VERSION ""

NS_ :

BS_:

BU_: VCAN2_00 VCAN2_0B

BO_ 2565866755 ETC2: 8 Vector__XXX
 SG_ TransCurrentGear : 24|8@1+ (1,-125) [-125|125] "" Vector__XXX

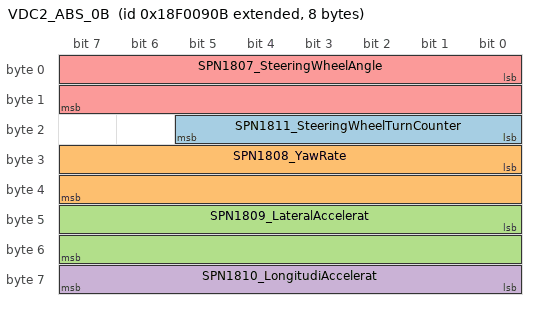
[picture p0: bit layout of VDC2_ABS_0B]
BO_ 2565867787 VDC2_ABS_0B: 8 VCAN2_0B
 SG_ SPN1811_SteeringWheelTurnCounter : 16|6@1+ (1,-32) [-32|31] "turns" Vector__XXX
 SG_ SPN1808_YawRate : 24|16@1+ (0.0069907,-224.599459) [-224.599459|233.5360655] "deg/s" Vector__XXX
 SG_ SPN1809_LateralAccelerat : 40|16@1+ (0.00048828125,-15.687) [-15.687|16.31251171875] "m/s^2" Vector__XXX
 SG_ SPN1810_LongitudiAccelerat : 56|8@1+ (0.1,-12.5) [-12.5|12.5] "m/s^2" Vector__XXX
 SG_ SPN1807_SteeringWheelAngle : 0|16@1+ (0.0559519970879496,-1797.59778644344) [-1797.59778644344|1797.59778644344] "deg" Vector__XXX

BO_ 2566844711 CCVS1_ECM_00: 8 VCAN2_00
 SG_ SPN84_WheBasVehicSpe : 8|16@1+ (0.00390625,0) [0|255.99609375] "km/h" Vector__XXX

CM_ SG_ 2565866755 TransCurrentGear "The gear currently engaged in the transmission or the last gear engaged while the transmission is in the process of";
BA_DEF_ SG_  "GenSigEVName" STRING ;
BA_DEF_ SG_  "GenSigILSupport" ENUM  "Yes","No";
BA_DEF_ SG_  "GenSigSendType" ENUM  "Cyclic","OnWrite","reserved","OnChange","reserved","reserved","reserved","NoSigSendType";
BA_DEF_ SG_  "GenSigStartValue" INT 0 10000;
BA_DEF_ SG_  "SigType" ENUM  "Default","Range","RangeSigned","ASCII","Discrete","Control","ReferencePGN","DTC","StringDelimiter","StringLength","StringLengthControl";
BA_DEF_ BO_  "GenMsgCycleTime" INT 0 3600000;
BA_DEF_ BO_  "VFrameFormat" ENUM  "StandardCAN","ExtendedCAN","reserved","J1939PG";
BA_DEF_ BO_  "GenMsgSendType" ENUM  "cyclic","reserved","cyclicIfActive","reserved","reserved","reserved","reserved","reserved","noMsgSendType";
BA_DEF_ BO_  "GenMsgRequestable" INT 0 1;
BA_DEF_ BO_  "GenMsgILSupport" ENUM  "Yes","No";
BA_DEF_ BU_  "NmStationAddress" INT 0 255;
BA_DEF_DEF_  "GenSigEVName" "Env@Nodename_@Signame";
BA_DEF_DEF_  "GenSigILSupport" "Yes";
BA_DEF_DEF_  "GenSigSendType" "NoSigSendType";
BA_DEF_DEF_  "GenSigStartValue" 0;
BA_DEF_DEF_  "SigType" "Default";
BA_DEF_DEF_  "GenMsgCycleTime" 0;
BA_DEF_DEF_  "VFrameFormat" "J1939PG";
BA_DEF_DEF_  "GenMsgSendType" "noMsgSendType";
BA_DEF_DEF_  "GenMsgRequestable" 1;
BA_DEF_DEF_  "GenMsgILSupport" "Yes";
BA_DEF_DEF_  "NmStationAddress" 254;
BA_ "GenMsgSendType" BO_ 2565866755 0;
BA_ "GenMsgCycleTime" BO_ 2565866755 100;
BA_ "GenMsgCycleTime" BO_ 2565867787 10;
BA_ "GenMsgCycleTime" BO_ 2566844711 100;
BA_ "GenSigStartValue" SG_ 2565867787 SPN1811_SteeringWheelTurnCounter 32;
